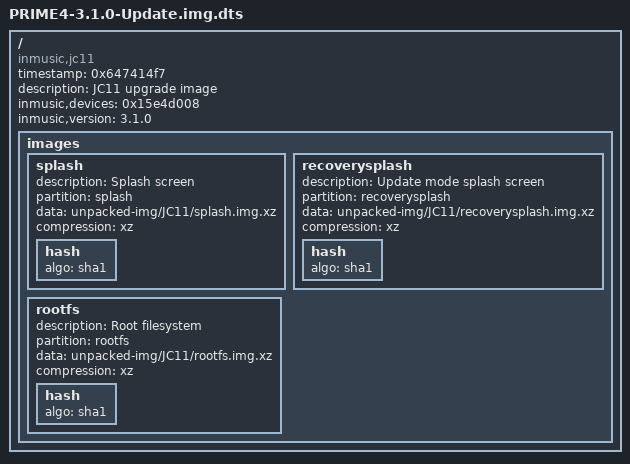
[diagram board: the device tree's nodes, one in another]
/dts-v1/;

/ {
	timestamp = <0x647414f7>;
	description = "JC11 upgrade image";
	compatible = "inmusic,jc11";
	inmusic,devices = <0x15e4d008>;
	inmusic,version = "3.1.0";

	images {

		splash {
			description = "Splash screen";
			partition = "splash";
			data = /incbin/("unpacked-img/JC11/splash.img.xz");
			compression = "xz";

			hash {
				algo = "sha1";
			};
		};

		recoverysplash {
			description = "Update mode splash screen";
			partition = "recoverysplash";
			data = /incbin/("unpacked-img/JC11/recoverysplash.img.xz");
			compression = "xz";

			hash {
				algo = "sha1";
			};
		};

		rootfs {
			description = "Root filesystem";
			partition = "rootfs";
			data = /incbin/("unpacked-img/JC11/rootfs.img.xz");
			compression = "xz";

			hash {
				algo = "sha1";
			};
		};
	};
};
